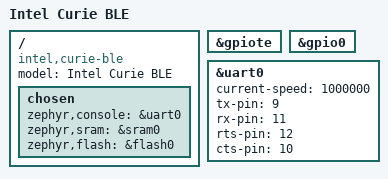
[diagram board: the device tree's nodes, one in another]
/*
 * Copyright (c) 2017 Linaro Limited
 *
 * SPDX-License-Identifier: Apache-2.0
 */

/dts-v1/;
#include <nordic/nrf51822_qfaa.dtsi>

/ {
	model = "Intel Curie BLE";
	compatible = "intel,curie-ble", "nordic,nrf51822-qfaa",
		     "nordic,nrf51822";

	chosen {
		zephyr,console = &uart0;
		zephyr,sram = &sram0;
		zephyr,flash = &flash0;
	};
};

&gpiote {
	status ="ok";
};

&gpio0 {
	status ="ok";
};

&uart0 {
	current-speed = <1000000>;
	status = "ok";
	tx-pin = <9>;
	rx-pin = <11>;
	rts-pin = <12>;
	cts-pin = <10>;
};
